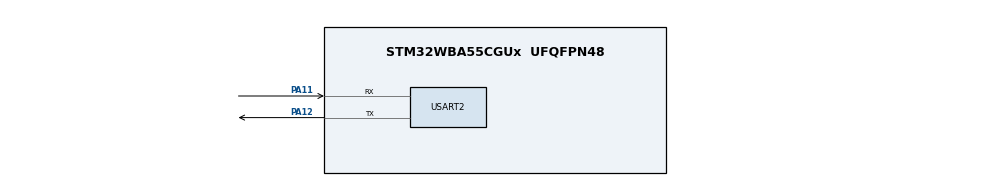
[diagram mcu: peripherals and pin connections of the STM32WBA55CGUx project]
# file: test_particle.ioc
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CORTEX_M33_NS.userName=CORTEX_M33
GPDMA1.CIRCULARMODE_GPDMACH1=DISABLE
GPDMA1.DESTINC_GPDMACH1=DMA_DINC_INCREMENTED
GPDMA1.DIRECTION_GPDMACH0=DMA_MEMORY_TO_PERIPH
GPDMA1.IPHANDLE_GPDMACH0-SIMPLEREQUEST_GPDMACH0=__NULL
GPDMA1.IPHANDLE_GPDMACH1-SIMPLEREQUEST_GPDMACH1=__NULL
GPDMA1.LINKALLOCATEDPORT_CIRCULAR_GPDMACH1=DMA_LINK_ALLOCATED_PORT0
GPDMA1.PRIORITY_GPDMACH0=DMA_LOW_PRIORITY_MID_WEIGHT
GPDMA1.PRIORITY_GPDMACH1=DMA_LOW_PRIORITY_MID_WEIGHT
GPDMA1.REQUEST_GPDMACH0=GPDMA1_REQUEST_USART2_TX
GPDMA1.REQUEST_GPDMACH1=GPDMA1_REQUEST_USART2_RX
GPDMA1.SRCINC_GPDMACH0=DMA_SINC_INCREMENTED
GPDMA1.TRANSFERALLOCATEDPORTDEST_GPDMACH1=DMA_DEST_ALLOCATED_PORT1
GPDMA1.TRANSFERALLOCATEDPORTSRC_GPDMACH0=DMA_SRC_ALLOCATED_PORT1
Mcu.Family=STM32WBA
Mcu.Name=STM32WBA55CGUx
Mcu.Package=UFQFPN48
NUCLEO-WBA55CG.BUTTON=1
NUCLEO-WBA55CG.BUTTON2=1
NUCLEO-WBA55CG.BUTTON3=1
NUCLEO-WBA55CG.LD1=true
NUCLEO-WBA55CG.LD2=true
NUCLEO-WBA55CG.LD3=true
NUCLEO-WBA55CG.VCP=true
NVIC.GPDMA1_Channel0_IRQn=true\:3\:0\:true\:false\:true\:true\:true\:true
NVIC.GPDMA1_Channel1_IRQn=true\:3\:0\:true\:false\:true\:true\:true\:true
NVIC.PriorityGroup=NVIC_PRIORITYGROUP_4
NVIC.USART2_IRQn=true\:10\:0\:true\:false\:true\:true\:true\:true
OSC_IN.GPIO_Label=RCC_OSC_IN
OSC_IN.Mode=HSE-External-Oscillator
OSC_IN.Signal=RCC_OSC_IN
OSC_OUT.GPIO_Label=RCC_OSC_OUT
OSC_OUT.Mode=HSE-External-Oscillator
OSC_OUT.Signal=RCC_OSC_OUT
PA11.GPIO_PuPd=GPIO_PULLUP
PA11.Mode=Asynchronous
PA11.Signal=USART2_RX
PA12.Mode=Asynchronous
PA12.Signal=USART2_TX
PA13\ (JTMS/SWDIO).GPIO_Label=DEBUG_JTMS-SWDIO
PA13\ (JTMS/SWDIO).Mode=Serial_Wire
PA13\ (JTMS/SWDIO).Signal=DEBUG_JTMS-SWDIO
PA14\ (JTCK/SWCLK).GPIO_Label=DEBUG_JTCK-SWCLK
PA14\ (JTCK/SWCLK).Mode=Serial_Wire
PA14\ (JTCK/SWCLK).Signal=DEBUG_JTCK-SWCLK
PA8.Signal=USART1_RX
PB12.Signal=USART1_TX
PC14-OSC32_IN.GPIO_Label=RCC_OSC32_IN
PC14-OSC32_IN.Mode=LSE-External-Oscillator
PC14-OSC32_IN.Signal=RCC_OSC32_IN
PC15-OSC32_OUT.GPIO_Label=RCC_OSC32_OUT
PC15-OSC32_OUT.Mode=LSE-External-Oscillator
PC15-OSC32_OUT.Signal=RCC_OSC32_OUT
ProjectManager.HeapSize=0x200
ProjectManager.StackSize=0x400
ProjectManager.TargetToolchain=STM32CubeIDE
RCC.ADCFreq_Value=32000000
RCC.AHBFreq_Value=32000000
RCC.APB1Freq_Value=32000000
RCC.APB1TimFreq_Value=32000000
RCC.APB2Freq_Value=32000000
RCC.APB2TimFreq_Value=32000000
RCC.CortexFreq_Value=4000000
RCC.HCLKFreq_Value=32000000
RCC.HSE_VALUE=32000000
RCC.HSI_VALUE=16000000
RCC.LSI1_VALUE=32000
RCC.LSI2_VALUE=32000
RCC.PLLFRACN=0
RCC.PLLM=2
RCC.PLLN=8
RCC.PLLSourceVirtual=RCC_PLLSOURCE_HSE
RCC.RTCClockSelection=RCC_RTCCLKSOURCE_LSE
RCC.SYSCLKFreq_VALUE=32000000
RCC.SYSCLKSourceVirtual=RCC_SYSCLKSOURCE_HSE
RCC.VCOOutputFreq_Value=128000000
USART2.OverSampling=UART_OVERSAMPLING_8
USART2.VirtualMode-Asynchronous=VM_ASYNC
VP_CORTEX_M33_NS_VS_Hclk.Mode=Hclk_Mode
VP_GPDMA1_VS_GPDMACH0.Mode=SIMPLEREQUEST_GPDMACH0
VP_GPDMA1_VS_GPDMACH1.Mode=SIMPLEREQUEST_GPDMACH1
VP_ICACHE_VS_ICACHE.Mode=DirectMappedCache
VP_MEMORYMAP_VS_MEMORYMAP.Mode=CurAppReg
VP_NUCLEO-WBA55CG_VS_BSP_COMMON.Mode=COMMON
VP_PWR_VS_SECSignals.Mode=Security/Privilege
board=NUCLEO-WBA55CG

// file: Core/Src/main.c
/* USER CODE BEGIN Header */
/**
  ******************************************************************************
  * @file           : main.c
  * @brief          : Main program body
  ******************************************************************************
  * @attention
  *
  * Copyright (c) 2025 STMicroelectronics.
  * All rights reserved.
  *
  * This software is licensed under terms that can be found in the LICENSE file
  * in the root directory of this software component.
  * If no LICENSE file comes with this software, it is provided AS-IS.
  *
  ******************************************************************************
  */
/* USER CODE END Header */
#include "main.h"

/* USER CODE BEGIN Includes */
#include "usart_dma.h"
#include "sps30_uart.h"
#include "average.h"
/* USER CODE END Includes */

COM_InitTypeDef BspCOMInit;

/* USER CODE BEGIN PV */
volatile uint32_t timeout = 0;
uart_dma_tx_t uart2_dma_tx;
uart_dma_rx_t uart2_dma_rx;

sensirion_sps30_data_t sps30_data;
avg_60_t avg_PM_1;
avg_60_t avg_PM_2p5;
avg_60_t avg_PM_4;
avg_60_t avg_PM_10;
avg_60_t avg_psize;
/* USER CODE END PV */

void SystemClock_Config(void);
static void MX_GPIO_Init(void);
static void MX_GPDMA1_Init(void);
static void MX_ICACHE_Init(void);
static void MX_USART2_UART_Init(void);

int main(void)
{

  /* MCU Configuration--------------------------------------------------------*/

  /* Reset of all peripherals, Initializes the Flash interface and the Systick. */
  HAL_Init();

  /* Enable PWR clock interface */

  LL_AHB4_GRP1_EnableClock(LL_AHB4_GRP1_PERIPH_PWR);

  /* Configure the system clock */
  SystemClock_Config();

  /* Initialize all configured peripherals */
  MX_GPIO_Init();
  MX_GPDMA1_Init();
  MX_ICACHE_Init();
  MX_USART2_UART_Init();
  /* USER CODE BEGIN 2 */
  uart_dma_tx_init(&uart2_dma_tx, USART2, GPDMA1, LL_DMA_CHANNEL_0, LL_GPDMA1_REQUEST_USART2_TX);
  uart_dma_rx_init(&uart2_dma_rx, USART2, GPDMA1, LL_DMA_CHANNEL_1, LL_GPDMA1_REQUEST_USART2_RX);
  /* USER CODE END 2 */

  /* Initialize leds */
  BSP_LED_Init(LED_BLUE);
  BSP_LED_Init(LED_GREEN);
  BSP_LED_Init(LED_RED);

  /* Initialize USER push-button, will be used to trigger an interrupt each time it's pressed.*/
  BSP_PB_Init(B1, BUTTON_MODE_EXTI);
  BSP_PB_Init(B2, BUTTON_MODE_EXTI);
  BSP_PB_Init(B3, BUTTON_MODE_EXTI);

  /* Initialize COM1 port (115200, 8 bits (7-bit data + 1 stop bit), no parity */
  BspCOMInit.BaudRate   = 115200;
  BspCOMInit.WordLength = COM_WORDLENGTH_8B;
  BspCOMInit.StopBits   = COM_STOPBITS_1;
  BspCOMInit.Parity     = COM_PARITY_NONE;
  BspCOMInit.HwFlowCtl  = COM_HWCONTROL_NONE;
  if (BSP_COM_Init(COM1, &BspCOMInit) != BSP_ERROR_NONE)
  {
    Error_Handler();
  }

  /* Infinite loop */
  /* USER CODE BEGIN WHILE */
  printf( "Start\n");

  AvgInit(&avg_PM_1);
  AvgInit(&avg_PM_2p5);
  AvgInit(&avg_PM_4);
  AvgInit(&avg_PM_10);
  AvgInit(&avg_psize);
  sps30_data.new_data = 0;

  HAL_Delay(500);
  sps30_device_reset(&uart2_dma_tx);
  HAL_Delay(500);
  sps30_start_measurement(&uart2_dma_tx, SPS30_OUTPUT_FORMAT_OUTPUT_FORMAT_FLOAT);
  HAL_Delay(500);

  uint8_t tmpbuf[100];
  uint32_t last_tick = 0;

  while (1)
  {
	uint32_t current_tick = HAL_GetTick();
	if ((current_tick - last_tick) >= 1000) {
		last_tick = current_tick;
		BSP_LED_Toggle(LD1);
		printf("VCP t: %lu  h: %lu\n", uart2_dma_rx.tail, uart2_dma_rx.head);
		sps30_read_measurement_values(&uart2_dma_tx);
		//uart_dma_tx_send(&uart2_dma_tx, (uint8_t *)"test DMA\n", 9);
		//sps30_start_measurement(SPS30_OUTPUT_FORMAT_OUTPUT_FORMAT_FLOAT);
	}
//	if (uart2_dma_rx.burst_end) {
//		uart2_dma_rx.burst_end = 0;
	if (uart2_dma_rx.new_data) {
		//uart2_dma_rx.new_data = 0;
		int num = uart_rx_available(&uart2_dma_rx);
		printf("RX %2u: ", num);
		uart_rx_snapshot(&uart2_dma_rx, tmpbuf, num);
		for (int i=0; i<num; i++)
			printf(" %02X", tmpbuf[i]);
		printf("\n");
		//uart_rx_read(&uart2_dma_rx, tmpbuf, num);
		sps30_receive(&uart2_dma_rx, &sps30_data);

		if (sps30_data.new_data == 1) {
			AvgAdd(&avg_PM_1,   sps30_data.mc_1p0);
			AvgAdd(&avg_PM_2p5, sps30_data.mc_2p5);
			AvgAdd(&avg_PM_4,   sps30_data.mc_4p0);
			AvgAdd(&avg_PM_10,  sps30_data.mc_10p0);
			AvgAdd(&avg_psize,  sps30_data.typ_sz);
			sps30_data.new_data = 0;
			printf("index: %u\n", avg_psize.index);
		}
	}
	if (avg_psize.full) {
		AvgCalc(&avg_PM_1);
		AvgCalc(&avg_PM_2p5);
		AvgCalc(&avg_PM_4);
		AvgCalc(&avg_PM_10);
		AvgCalc(&avg_psize);

		printf("Cumulative: PM1 %.3f, PM2.5 %.3f, PM4 %.3f, PM10 %.3f, size %f\n", avg_PM_1.avg, avg_PM_2p5.avg, avg_PM_4.avg, avg_PM_10.avg, avg_psize.avg);

		float pm10 = avg_PM_10.avg - avg_PM_4.avg;
		float pm4 = avg_PM_4.avg - avg_PM_2p5.avg;
		float pm2p5 = avg_PM_2p5.avg - avg_PM_1.avg;

		printf("Average:    PM1 %.3f, PM2.5 %.3f, PM4 %.3f, PM10 %.3f, size %f\n", avg_PM_1.avg, pm2p5, pm4, pm10, avg_psize.avg);

	}
    /* USER CODE END WHILE */

  }
}

void SystemClock_Config(void)
{
  LL_FLASH_SetLatency(LL_FLASH_LATENCY_0);
  while(LL_FLASH_GetLatency()!= LL_FLASH_LATENCY_0)
  {
  }

  LL_PWR_SetRegulVoltageScaling(LL_PWR_REGU_VOLTAGE_SCALE1);
  LL_RCC_HSE_Enable();

   /* Wait till HSE is ready */
  while(LL_RCC_HSE_IsReady() != 1)
  {
  }

  LL_RCC_SetSysClkSource(LL_RCC_SYS_CLKSOURCE_HSE);

   /* Wait till System clock is ready */
  while(LL_RCC_GetSysClkSource() != LL_RCC_SYS_CLKSOURCE_STATUS_HSE)
  {
  }

  LL_RCC_SetAHBPrescaler(LL_RCC_SYSCLK_DIV_1);
  LL_RCC_SetAHB5Divider(LL_RCC_AHB5_DIVIDER_1);
  LL_RCC_SetAPB1Prescaler(LL_RCC_APB1_DIV_1);
  LL_RCC_SetAPB2Prescaler(LL_RCC_APB2_DIV_1);
  LL_RCC_SetAPB7Prescaler(LL_RCC_APB7_DIV_1);
  LL_SetSystemCoreClock(32000000);

   /* Update the time base */
  if (HAL_InitTick (TICK_INT_PRIORITY) != HAL_OK)
  {
    Error_Handler();
  }
}

static void MX_GPDMA1_Init(void)
{

  LL_DMA_InitLinkedListTypeDef DMA_InitLinkedListStruct = {0};

  /* Peripheral clock enable */
  LL_AHB1_GRP1_EnableClock(LL_AHB1_GRP1_PERIPH_GPDMA1);

  /* GPDMA1 interrupt Init */
  NVIC_SetPriority(GPDMA1_Channel0_IRQn, NVIC_EncodePriority(NVIC_GetPriorityGrouping(),3, 0));
  NVIC_EnableIRQ(GPDMA1_Channel0_IRQn);
  NVIC_SetPriority(GPDMA1_Channel1_IRQn, NVIC_EncodePriority(NVIC_GetPriorityGrouping(),3, 0));
  NVIC_EnableIRQ(GPDMA1_Channel1_IRQn);

  DMA_InitLinkedListStruct.Priority = LL_DMA_LOW_PRIORITY_MID_WEIGHT;
  DMA_InitLinkedListStruct.LinkStepMode = LL_DMA_LSM_FULL_EXECUTION;
  DMA_InitLinkedListStruct.LinkAllocatedPort = LL_DMA_LINK_ALLOCATED_PORT0;
  DMA_InitLinkedListStruct.TransferEventMode = LL_DMA_TCEM_LAST_LLITEM_TRANSFER;
  LL_DMA_List_Init(GPDMA1, LL_DMA_CHANNEL_1, &DMA_InitLinkedListStruct);

}

static void MX_ICACHE_Init(void)
{

  /** Enable instruction cache in 1-way (direct mapped cache)
  */
  LL_ICACHE_SetMode(LL_ICACHE_1WAY);
  LL_ICACHE_Enable();

}

static void MX_USART2_UART_Init(void)
{

  LL_USART_InitTypeDef USART_InitStruct = {0};

  LL_GPIO_InitTypeDef GPIO_InitStruct = {0};
  LL_DMA_InitTypeDef DMA_InitStruct = {0};

  LL_RCC_SetUSARTClockSource(LL_RCC_USART2_CLKSOURCE_PCLK1);

  /* Peripheral clock enable */
  LL_APB1_GRP1_EnableClock(LL_APB1_GRP1_PERIPH_USART2);

  LL_AHB2_GRP1_EnableClock(LL_AHB2_GRP1_PERIPH_GPIOA);
  /**USART2 GPIO Configuration
  PA12   ------> USART2_TX
  PA11   ------> USART2_RX
  */
  GPIO_InitStruct.Pin = LL_GPIO_PIN_12;
  GPIO_InitStruct.Mode = LL_GPIO_MODE_ALTERNATE;
  GPIO_InitStruct.Speed = LL_GPIO_SPEED_FREQ_LOW;
  GPIO_InitStruct.OutputType = LL_GPIO_OUTPUT_PUSHPULL;
  GPIO_InitStruct.Pull = LL_GPIO_PULL_NO;
  GPIO_InitStruct.Alternate = LL_GPIO_AF_3;
  LL_GPIO_Init(GPIOA, &GPIO_InitStruct);

  GPIO_InitStruct.Pin = LL_GPIO_PIN_11;
  GPIO_InitStruct.Mode = LL_GPIO_MODE_ALTERNATE;
  GPIO_InitStruct.Speed = LL_GPIO_SPEED_FREQ_LOW;
  GPIO_InitStruct.OutputType = LL_GPIO_OUTPUT_PUSHPULL;
  GPIO_InitStruct.Pull = LL_GPIO_PULL_UP;
  GPIO_InitStruct.Alternate = LL_GPIO_AF_3;
  LL_GPIO_Init(GPIOA, &GPIO_InitStruct);

  /* USART2 DMA Init */

  /* GPDMA1_REQUEST_USART2_TX Init */
  DMA_InitStruct.SrcAddress = 0x00000000U;
  DMA_InitStruct.DestAddress = 0x00000000U;
  DMA_InitStruct.Direction = LL_DMA_DIRECTION_MEMORY_TO_PERIPH;
  DMA_InitStruct.BlkHWRequest = LL_DMA_HWREQUEST_SINGLEBURST;
  DMA_InitStruct.DataAlignment = LL_DMA_DATA_ALIGN_ZEROPADD;
  DMA_InitStruct.SrcBurstLength = 1;
  DMA_InitStruct.DestBurstLength = 1;
  DMA_InitStruct.SrcDataWidth = LL_DMA_SRC_DATAWIDTH_BYTE;
  DMA_InitStruct.DestDataWidth = LL_DMA_DEST_DATAWIDTH_BYTE;
  DMA_InitStruct.SrcIncMode = LL_DMA_SRC_INCREMENT;
  DMA_InitStruct.DestIncMode = LL_DMA_DEST_FIXED;
  DMA_InitStruct.Priority = LL_DMA_LOW_PRIORITY_MID_WEIGHT;
  DMA_InitStruct.BlkDataLength = 0x00000000U;
  DMA_InitStruct.TriggerMode = LL_DMA_TRIGM_BLK_TRANSFER;
  DMA_InitStruct.TriggerPolarity = LL_DMA_TRIG_POLARITY_MASKED;
  DMA_InitStruct.TriggerSelection = 0x00000000U;
  DMA_InitStruct.Request = LL_GPDMA1_REQUEST_USART2_TX;
  DMA_InitStruct.TransferEventMode = LL_DMA_TCEM_BLK_TRANSFER;
  DMA_InitStruct.SrcAllocatedPort = LL_DMA_SRC_ALLOCATED_PORT1;
  DMA_InitStruct.DestAllocatedPort = LL_DMA_DEST_ALLOCATED_PORT0;
  DMA_InitStruct.LinkAllocatedPort = LL_DMA_LINK_ALLOCATED_PORT1;
  DMA_InitStruct.LinkStepMode = LL_DMA_LSM_FULL_EXECUTION;
  DMA_InitStruct.LinkedListBaseAddr = 0x00000000U;
  DMA_InitStruct.LinkedListAddrOffset = 0x00000000U;
  LL_DMA_Init(GPDMA1, LL_DMA_CHANNEL_0, &DMA_InitStruct);

  /* USART2 interrupt Init */
  NVIC_SetPriority(USART2_IRQn, NVIC_EncodePriority(NVIC_GetPriorityGrouping(),10, 0));
  NVIC_EnableIRQ(USART2_IRQn);

  USART_InitStruct.PrescalerValue = LL_USART_PRESCALER_DIV1;
  USART_InitStruct.BaudRate = 115200;
  USART_InitStruct.DataWidth = LL_USART_DATAWIDTH_8B;
  USART_InitStruct.StopBits = LL_USART_STOPBITS_1;
  USART_InitStruct.Parity = LL_USART_PARITY_NONE;
  USART_InitStruct.TransferDirection = LL_USART_DIRECTION_TX_RX;
  USART_InitStruct.HardwareFlowControl = LL_USART_HWCONTROL_NONE;
  USART_InitStruct.OverSampling = LL_USART_OVERSAMPLING_8;
  LL_USART_Init(USART2, &USART_InitStruct);
  LL_USART_SetTXFIFOThreshold(USART2, LL_USART_FIFOTHRESHOLD_1_8);
  LL_USART_SetRXFIFOThreshold(USART2, LL_USART_FIFOTHRESHOLD_1_8);
  LL_USART_DisableFIFO(USART2);
  LL_USART_ConfigAsyncMode(USART2);
  LL_USART_Enable(USART2);

}

static void MX_GPIO_Init(void)
{

  /* GPIO Ports Clock Enable */
  LL_AHB2_GRP1_EnableClock(LL_AHB2_GRP1_PERIPH_GPIOC);
  LL_AHB2_GRP1_EnableClock(LL_AHB2_GRP1_PERIPH_GPIOA);

}

void Error_Handler(void)
{
  __disable_irq();
  while (1)
  {
  }
}
